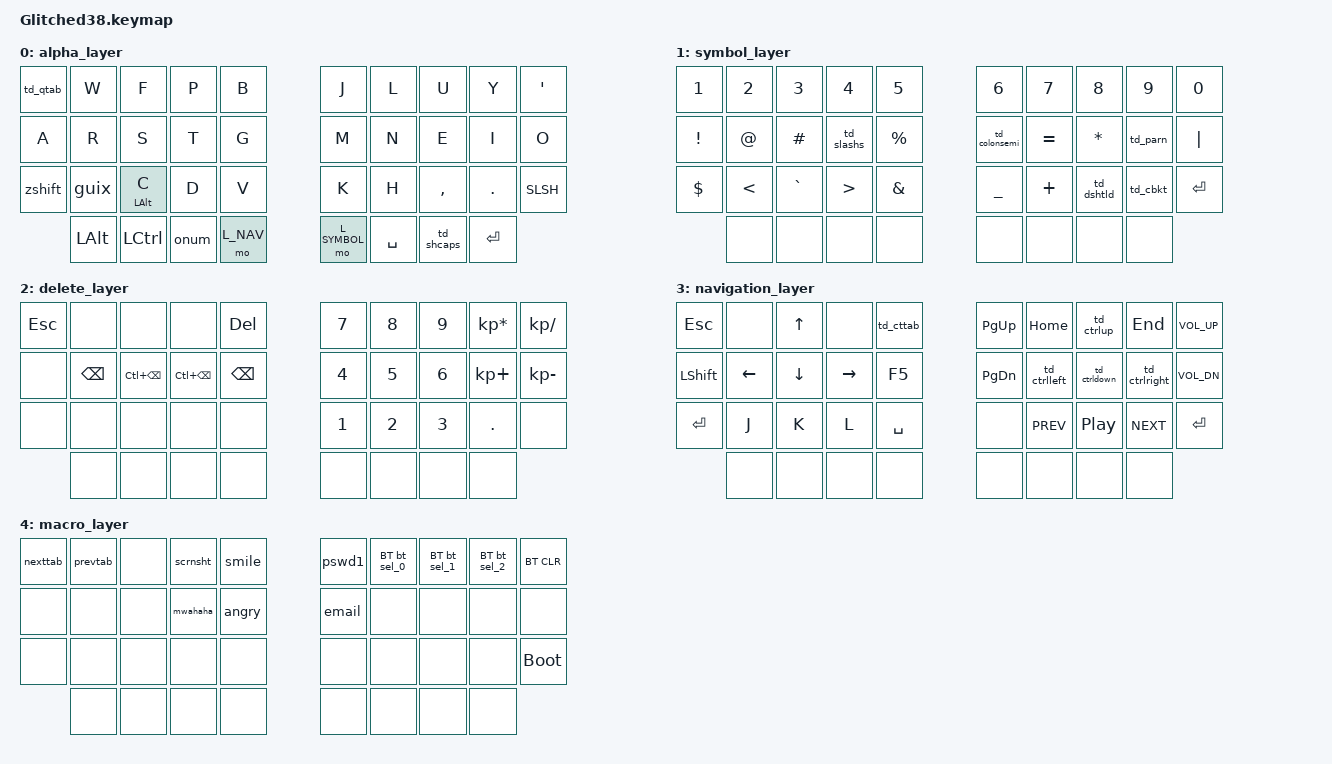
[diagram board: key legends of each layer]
//#include <behaviors.dtsi
//#include <dt-bindiings/zmk/keys.h>
//#include <dt-bindings/zmk/bt.h>

///{
//    keymap {
//        compatible = "zmk,keymap";
//
//        default_layer {
//            bindings = <
//                &kp KP_N7   
//        }
//    }
//}
//made with AI, good luck! 

#include <behaviors.dtsi>
#include <dt-bindings/zmk/keys.h>
#include <dt-bindings/zmk/bt.h>

// Layer definitions
#define L_ALPHA 0
#define L_SYMBOL 1
#define L_DELETE 2
#define L_NAV 3
#define L_MACRO 5

/ {
    /*
     * 3x5+4 Matrix Index Positions Map Reference:
     * Left Hand Alphas:                   Right Hand Alphas:
     *  0   1   2   3   4                   5   6   7   8   9
     * 10  11  12  13  14                  15  16  17  18  19
     * 20  21  22  23  24                  25  26  27  28  29
     *             Left Thumbs:      Right Thumbs:
     *             30  31  32  33    34  35  36  37
     */

    behaviors {
        // Double-tap definitions
        td_qtab: tapdance_tab_and_q {
            compatible = "zmk,behavior-tap-dance";
            #binding-cells = <0>;
            tapping-term-ms = <200>;
            bindings = <&kp TAB>, <&kp Q>;
        };
        td_sbkt: tapdance_brackets {
            compatible = "zmk,behavior-tap-dance";
            #binding-cells = <0>;
            tapping-term-ms = <200>;
            bindings = <&kp LBRC>, <&kp RBRC>;
        };
        td_cbkt: tapdance_curly_brackets {
            compatible = "zmk,behavior-tap-dance";
            #binding-cells = <0>;
            tapping-term-ms = <200>;
            bindings = <&kp LCBR>, <&kp RCBR>;
        };
        td_parn: tapdance_parentheses {
            compatible = "zmk,behavior-tap-dance";
            #binding-cells = <0>;
            tapping-term-ms = <200>;
            bindings = <&kp LPAR>, <&kp RPAR>;
        };
        td_ltgt: tapdance_angles {
            compatible = "zmk,behavior-tap-dance";
            #binding-cells = <0>;
            tapping-term-ms = <200>;
            bindings = <&kp LESS_THAN>, <&kp GREATER_THAN>;
        };
        td_shcaps: tapdance_shift_and_caps {
            compatible = "zmk,behavior-tap-dance";
            #binding-cells = <0>;
            tapping-term-ms = <200>;
            bindings = <&kp LSHFT>, <&kp CAPS>;
        };
        td_slashs: tapdance_slash_and_backslash {
            compatible = "zmk,behavior-tap-dance";
            #binding-cells = <0>;
            tapping-term-ms = <200>;
            bindings = <&kp SLSH>, <&kp BSLH>;
        };
        td_cttab: ctrl_tab {
            compatible = "zmk,behavior-tap-dance";
            #binding-cells = <0>;
            tapping-term-ms = <200>;
            bindings = <&kp LC(TAB)>, <&kp LC(LS(TAB))>;
        };
        td_colonsemi: td_colonsemi {
            compatible = "zmk,behavior-tap-dance";
            #binding-cells = <0>;
            tapping-term-ms = <200>;
            bindings = <&kp COLON>, <&kp SCLN>;
        };
        td_ctrlleft: td_ctrlleft {
            compatible = "zmk,behavior-tap-dance";
            #binding-cells = <0>;
            tapping-term-ms = <200>;
            bindings = <&kp LEFT>, <&kp LC(LEFT)>;
        };
        td_ctrlright: td_ctrlright {
            compatible = "zmk,behavior-tap-dance";
            #binding-cells = <0>;
            tapping-term-ms = <200>;
            bindings = <&kp RIGHT>, <&kp LC(RIGHT)>;
        };
        td_ctrlup: td_ctrlup {
            compatible = "zmk,behavior-tap-dance";
            #binding-cells = <0>;
            tapping-term-ms = <200>;
            bindings = <&kp UP>, <&kp LC(UP)>;
        };
        td_ctrldown: td_ctrldown {
            compatible = "zmk,behavior-tap-dance";
            #binding-cells = <0>;
            tapping-term-ms = <200>;
            bindings = <&kp DOWN>, <&kp LC(DOWN)>;
        };
        td_dshtld: tapdance_dash_and_tilde {
            compatible = "zmk,behavior-tap-dance";
            #binding-cells = <0>;
            tapping-term-ms = <200>;
            bindings = <&kp MINUS>, <&kp TILDE>;
        };

        // Custom Mod-Taps matching your C definitions
        guix: x_and_gui {
            compatible = "zmk,behavior-hold-tap";
            #binding-cells = <2>;
            flavor = "tap-preferred";
            tapping-term-ms = <200>; 
            bindings = <&kp x>, <&kp LEFT_GUI>;
        };
        zshift: z_and_shift {
            compatible = "zmk,behavior-hold-tap";
            #binding-cells = <2>;
            flavor = "tap-preferred";
            tapping-term-ms = <200>; 
            bindings = <&kp LEFT_SHIFT>, <&kp z>;
        };
        altc: c_and_alt {
            compatible = "zmk,behavior-hold-tap";
            #binding-cells = <2>;
            flavor = "tap-preferred";
            tapping-term-ms = <200>; 
            bindings = <&kp LEFT_ALT>, <&kp C>;
        };
        onum: backspace_and_delete_layer {
            compatible = "zmk,behavior-hold-tap";
            #binding-cells = <2>;
            flavor = "tap-preferred";
            tapping-term-ms = <200>;
            bindings = <&mo delete_layer>, <&kp BSPC>;
        };
    };

    macros {
        nexttab: nexttab {
            compatible = "zmk,behavior-macro";
            #binding-cells = <0>;
            bindings = <&macro_press &kp LCTRL>, <&macro_tap &kp TAB>, <&macro_release &kp LCTRL>;
        };
        prevtab: prevtab {
            compatible = "zmk,behavior-macro";
            #binding-cells = <0>;
            bindings = <&macro_press &kp LCTRL &kp LSHFT>, <&macro_tap &kp TAB>, <&macro_release &kp LCTRL &kp LSHFT>;
        };
        smile: smile {
            compatible = "zmk,behavior-macro";
            #binding-cells = <0>;
            bindings = <&macro_tap &kp COLON &kp RPAR>;
        };
        angry: angry {
            compatible = "zmk,behavior-macro";
            #binding-cells = <0>;
            bindings = <&macro_tap &kp GREATER_THAN &kp COLON &kp LPAR>;
        };
        mwahaha: mwahaha {
            compatible = "zmk,behavior-macro";
            #binding-cells = <0>;
            bindings = <&macro_tap &kp GREATER_THAN &kp COLON &kp RPAR>;
        };
        pswd1: password1 {
            compatible = "zmk,behavior-macro";
            #binding-cells = <0>;
            bindings = <&macro_types STRING_HOLD("Mikeysch00!")>, <&macro_tap &kp ENTER>;
        };
        email: email {
            compatible = "zmk,behavior-macro";
            #binding-cells = <0>;
            bindings = <&macro_types STRING_HOLD("Osterlmi@amazon.com")>;
        };
        scrnsht: screenshot {
            compatible = "zmk,behavior-macro";
            #binding-cells = <0>;
            bindings
                = <&macro_press &kp LGUI &kp left_shift>, <&macro_tap &kp S>, <&macro_release &kp LGUI &kp left_shift>;
        };
//        wfh: wfh {
//            compatible = "zmk,behavior-macro";
//            #binding-cells = <0>;
//            bindings = <&macro_types STRING_HOLD("EMAIL ADDRESS")>, <&macro_tap &kp ENTER>, <&macro_types STRING_HOLD("password")>, <&macro_tap &kp ENTER>;
//        };
    };

    combos {
        compatible = "zmk,combos";
        
        // COMBO_MACRO uses KC_OSYM (Position 34) + KC_ONAV (Position 33)
        combo_macro {
            timeout-ms = <250>; 
            key-positions = <33 34>; 
            bindings = <&tog LAYER_MACRO>; 
        };
        
        // COMBO_QUESTION uses KC_SHCAPS (Position 36) + KC_ENT (Position 37)
        combo_question {
            timeout-ms = <50>; 
            key-positions = <36 37>; 
            bindings = <&kp QMARK>;
        };
    };

    keymap {
        compatible = "zmk,keymap";

        alpha_layer {
            bindings = <
    &td_qtab       &kp W        &kp F        &kp P        &kp B                      &kp J        &kp L        &kp U        &kp Y        &kp SQT
    &kp A          &kp R        &kp S        &kp T        &kp G                      &kp M        &kp N        &kp E        &kp I        &kp O
    &zshift        &guix       &altc LALT C  &kp D        &kp V                      &kp K        &kp H        &kp COMMA    &kp DOT      &kp SLSH
                   &kp LALT     &kp LCTRL    &onum        &mo L_NAV                  &mo L_SYMBOL &kp SPC      &td_shcaps   &kp ENTER
            >;
        };

        symbol_layer {
            bindings = <
    &kp N1         &kp N2       &kp N3       &kp N4       &kp N5                     &kp N6       &kp N7       &kp N8       &kp N9       &kp N0
    &kp EXCL       &kp AT       &kp HASH     &td_slashs   &kp PRCNT                 &td_colonsemi &kp EQUAL    &kp ASTRK    &td_parn     &kp PIPE
    &kp DLLR       &kp LESS_THAN &kp GRAVE   &kp GREATER_THAN &kp AMPS               &kp UNDER    &kp PLUS     &td_dshtld   &td_cbkt     &kp ENTER
                   &none        &none        &none        &none                      &none        &none        &none        &none
            >;
        };

        delete_layer {
            bindings = <
    &kp ESC        &none        &none        &none        &kp DEL                    &kp N7       &kp N8       &kp N9    &kp KP_MULTIPLY &kp KP_DIVIDE
    &none          &kp BSPC     &kp LC(BSPC) &kp LC(BSPC) &kp BSPC                   &kp N4       &kp N5       &kp N6       &kp KP_PLUS  &kp KP_MINUS
    &none          &none        &none        &none        &none                      &kp N1       &kp N2       &kp N3       &kp DOT      &none
                   &none        &none        &none        &none                      &none        &none        &none        &none
            >;
        };

        navigation_layer {
            bindings = <
    &kp ESC        &none        &kp UP       &none        &td_cttab                  &kp PG_UP    &kp HOME     &td_ctrlup   &kp END        &kp C_VOL_UP
    &kp LEFT_SHIFT &kp LEFT     &kp DOWN     &kp RIGHT    &kp F5                     &kp PG_DN    &td_ctrlleft &td_ctrldown &td_ctrlright  &kp C_VOL_DN
    &kp ENTER      &kp J        &kp K        &kp L        &kp SPACE                  &none        &kp K_PREV   &kp C_PLAY_PAUSE  &kp K_NEXT &kp ENTER
                   &none        &none        &none        &none                      &none        &none        &none        &none
            >;
        };

        macro_layer {
            bindings = <
    &nexttab       &prevtab     &none        &scrnsht     &smile                     &pswd1       &bt bt_sel_0 &bt bt_sel_1 &bt bt_sel_2 &bt BT_CLR
    &none          &none        &none        &mwahaha     &angry                     &email       &none        &none        &none        &none
    &none          &none        &none        &none        &none                      &none        &none        &none        &none        &bootloader
                   &none        &none        &none        &none                      &none        &none        &none        &none
            >;
        };
    };
};
